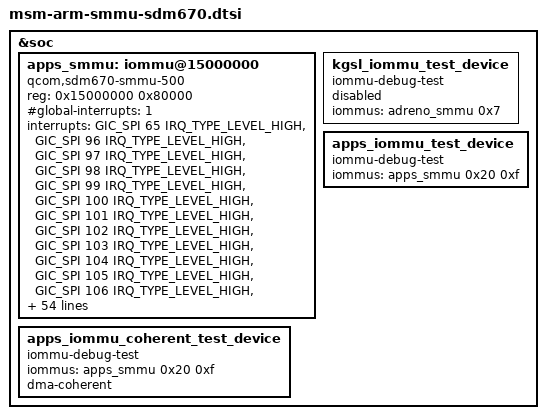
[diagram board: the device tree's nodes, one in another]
/* Copyright (c) 2017-2018,2020 The Linux Foundation. All rights reserved.
 *
 * This program is free software; you can redistribute it and/or modify
 * it under the terms of the GNU General Public License version 2 and
 * only version 2 as published by the Free Software Foundation.
 *
 * This program is distributed in the hope that it will be useful,
 * but WITHOUT ANY WARRANTY; without even the implied warranty of
 * MERCHANTABILITY or FITNESS FOR A PARTICULAR PURPOSE.  See the
 * GNU General Public License for more details.
 */

#include <dt-bindings/interrupt-controller/arm-gic.h>
#include <dt-bindings/msm/msm-bus-ids.h>

&soc {
	apps_smmu: iommu@15000000 {
		compatible = "qcom,sdm670-smmu-500", "qcom,smmu-500", "arm,mmu-500";
		reg = <0x15000000 0x80000>;
		#iommu-cells = <2>;
		#global-interrupts = <1>;
		interrupts = <GIC_SPI 65 IRQ_TYPE_LEVEL_HIGH>,
			     <GIC_SPI 96 IRQ_TYPE_LEVEL_HIGH>,
			     <GIC_SPI 97 IRQ_TYPE_LEVEL_HIGH>,
			     <GIC_SPI 98 IRQ_TYPE_LEVEL_HIGH>,
			     <GIC_SPI 99 IRQ_TYPE_LEVEL_HIGH>,
			     <GIC_SPI 100 IRQ_TYPE_LEVEL_HIGH>,
			     <GIC_SPI 101 IRQ_TYPE_LEVEL_HIGH>,
			     <GIC_SPI 102 IRQ_TYPE_LEVEL_HIGH>,
			     <GIC_SPI 103 IRQ_TYPE_LEVEL_HIGH>,
			     <GIC_SPI 104 IRQ_TYPE_LEVEL_HIGH>,
			     <GIC_SPI 105 IRQ_TYPE_LEVEL_HIGH>,
			     <GIC_SPI 106 IRQ_TYPE_LEVEL_HIGH>,
			     <GIC_SPI 107 IRQ_TYPE_LEVEL_HIGH>,
			     <GIC_SPI 108 IRQ_TYPE_LEVEL_HIGH>,
			     <GIC_SPI 109 IRQ_TYPE_LEVEL_HIGH>,
			     <GIC_SPI 110 IRQ_TYPE_LEVEL_HIGH>,
			     <GIC_SPI 111 IRQ_TYPE_LEVEL_HIGH>,
			     <GIC_SPI 112 IRQ_TYPE_LEVEL_HIGH>,
			     <GIC_SPI 113 IRQ_TYPE_LEVEL_HIGH>,
			     <GIC_SPI 114 IRQ_TYPE_LEVEL_HIGH>,
			     <GIC_SPI 115 IRQ_TYPE_LEVEL_HIGH>,
			     <GIC_SPI 116 IRQ_TYPE_LEVEL_HIGH>,
			     <GIC_SPI 117 IRQ_TYPE_LEVEL_HIGH>,
			     <GIC_SPI 118 IRQ_TYPE_LEVEL_HIGH>,
			     <GIC_SPI 181 IRQ_TYPE_LEVEL_HIGH>,
			     <GIC_SPI 182 IRQ_TYPE_LEVEL_HIGH>,
			     <GIC_SPI 183 IRQ_TYPE_LEVEL_HIGH>,
			     <GIC_SPI 184 IRQ_TYPE_LEVEL_HIGH>,
			     <GIC_SPI 185 IRQ_TYPE_LEVEL_HIGH>,
			     <GIC_SPI 186 IRQ_TYPE_LEVEL_HIGH>,
			     <GIC_SPI 187 IRQ_TYPE_LEVEL_HIGH>,
			     <GIC_SPI 188 IRQ_TYPE_LEVEL_HIGH>,
			     <GIC_SPI 189 IRQ_TYPE_LEVEL_HIGH>,
			     <GIC_SPI 190 IRQ_TYPE_LEVEL_HIGH>,
			     <GIC_SPI 191 IRQ_TYPE_LEVEL_HIGH>,
			     <GIC_SPI 192 IRQ_TYPE_LEVEL_HIGH>,
			     <GIC_SPI 315 IRQ_TYPE_LEVEL_HIGH>,
			     <GIC_SPI 316 IRQ_TYPE_LEVEL_HIGH>,
			     <GIC_SPI 317 IRQ_TYPE_LEVEL_HIGH>,
			     <GIC_SPI 318 IRQ_TYPE_LEVEL_HIGH>,
			     <GIC_SPI 319 IRQ_TYPE_LEVEL_HIGH>,
			     <GIC_SPI 320 IRQ_TYPE_LEVEL_HIGH>,
			     <GIC_SPI 321 IRQ_TYPE_LEVEL_HIGH>,
			     <GIC_SPI 322 IRQ_TYPE_LEVEL_HIGH>,
			     <GIC_SPI 323 IRQ_TYPE_LEVEL_HIGH>,
			     <GIC_SPI 324 IRQ_TYPE_LEVEL_HIGH>,
			     <GIC_SPI 325 IRQ_TYPE_LEVEL_HIGH>,
			     <GIC_SPI 326 IRQ_TYPE_LEVEL_HIGH>,
			     <GIC_SPI 327 IRQ_TYPE_LEVEL_HIGH>,
			     <GIC_SPI 328 IRQ_TYPE_LEVEL_HIGH>,
			     <GIC_SPI 329 IRQ_TYPE_LEVEL_HIGH>,
			     <GIC_SPI 330 IRQ_TYPE_LEVEL_HIGH>,
			     <GIC_SPI 331 IRQ_TYPE_LEVEL_HIGH>,
			     <GIC_SPI 332 IRQ_TYPE_LEVEL_HIGH>,
			     <GIC_SPI 333 IRQ_TYPE_LEVEL_HIGH>,
			     <GIC_SPI 334 IRQ_TYPE_LEVEL_HIGH>,
			     <GIC_SPI 335 IRQ_TYPE_LEVEL_HIGH>,
			     <GIC_SPI 336 IRQ_TYPE_LEVEL_HIGH>,
			     <GIC_SPI 337 IRQ_TYPE_LEVEL_HIGH>,
			     <GIC_SPI 338 IRQ_TYPE_LEVEL_HIGH>,
			     <GIC_SPI 339 IRQ_TYPE_LEVEL_HIGH>,
			     <GIC_SPI 340 IRQ_TYPE_LEVEL_HIGH>,
			     <GIC_SPI 341 IRQ_TYPE_LEVEL_HIGH>,
			     <GIC_SPI 342 IRQ_TYPE_LEVEL_HIGH>,
			     <GIC_SPI 343 IRQ_TYPE_LEVEL_HIGH>;
		dma-coherent;
	};

	kgsl_iommu_test_device {
		status = "disabled";
		compatible = "iommu-debug-test";
		/*
		 * 0x7 isn't a valid sid, but should pass the sid sanity check.
		 * We just need _something_ here to get this node recognized by
		 * the SMMU driver. Our test uses ATOS, which doesn't use SIDs
		 * anyways, so using a dummy value is ok.
		 */
		iommus = <&adreno_smmu 0x7>;
	};

	apps_iommu_test_device {
		compatible = "iommu-debug-test";
		/*
		 * This SID belongs to TSIF. We can't use a fake SID for
		 * the apps_smmu device.
		 */
		iommus = <&apps_smmu 0x20 0xf>;
	};

	apps_iommu_coherent_test_device {
		compatible = "iommu-debug-test";
		/*
		 * This SID belongs to TSIF. We can't use a fake SID for
		 * the apps_smmu device.
		 */
		iommus = <&apps_smmu 0x20 0xf>;
		dma-coherent;
	};
};

